AUTOSAR XML (schema 4-3-0)
package /ComponentTypes
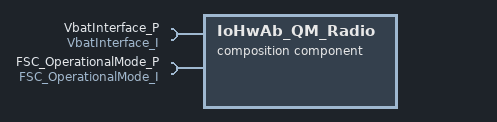
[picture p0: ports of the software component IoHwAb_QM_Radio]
  composition sw component type IoHwAb_QM_Radio
    require port VbatInterface_P: required-interface=VbatInterface_I
      required-com-specs:
        DobhsCtrlInterface_P_4
        DobhsCtrlInterface_P_5
        DobhsCtrlInterface_P_3
        DobhsCtrlInterface_P_2
        DobhsCtrlInterface_P_1
        FSC_OperationalMode
        VbatInterface_P
    require port FSC_OperationalMode_P: required-com-specs=[FSC_OperationalMode, VbatInterface_P], required-interface=FSC_OperationalMode_I
    4 x component:
      IoHwAb_QM_LF_COMTP: type=IoHwAb_QM_LF_COMTP
      IoHwAb_QM_LF_IF: type=IoHwAb_QM_LF_IF
      IoHwAb_QM_RF_COMTP: type=IoHwAb_QM_RF_COMTP
      IoHwAb_QM_RF_IF: type=IoHwAb_QM_RF_IF
    delegate IoHwAb_QM_LF_IF.VbatInterface_P <-> outer port VbatInterface_P
    delegate IoHwAb_QM_RF_IF.VbatInterface_P <-> outer port VbatInterface_P
    delegate IoHwAb_QM_LF_IF.FSC_OperationalMode_P <-> outer port FSC_OperationalMode_P
    delegate IoHwAb_QM_RF_IF.FSC_OperationalMode_P <-> outer port FSC_OperationalMode_P
